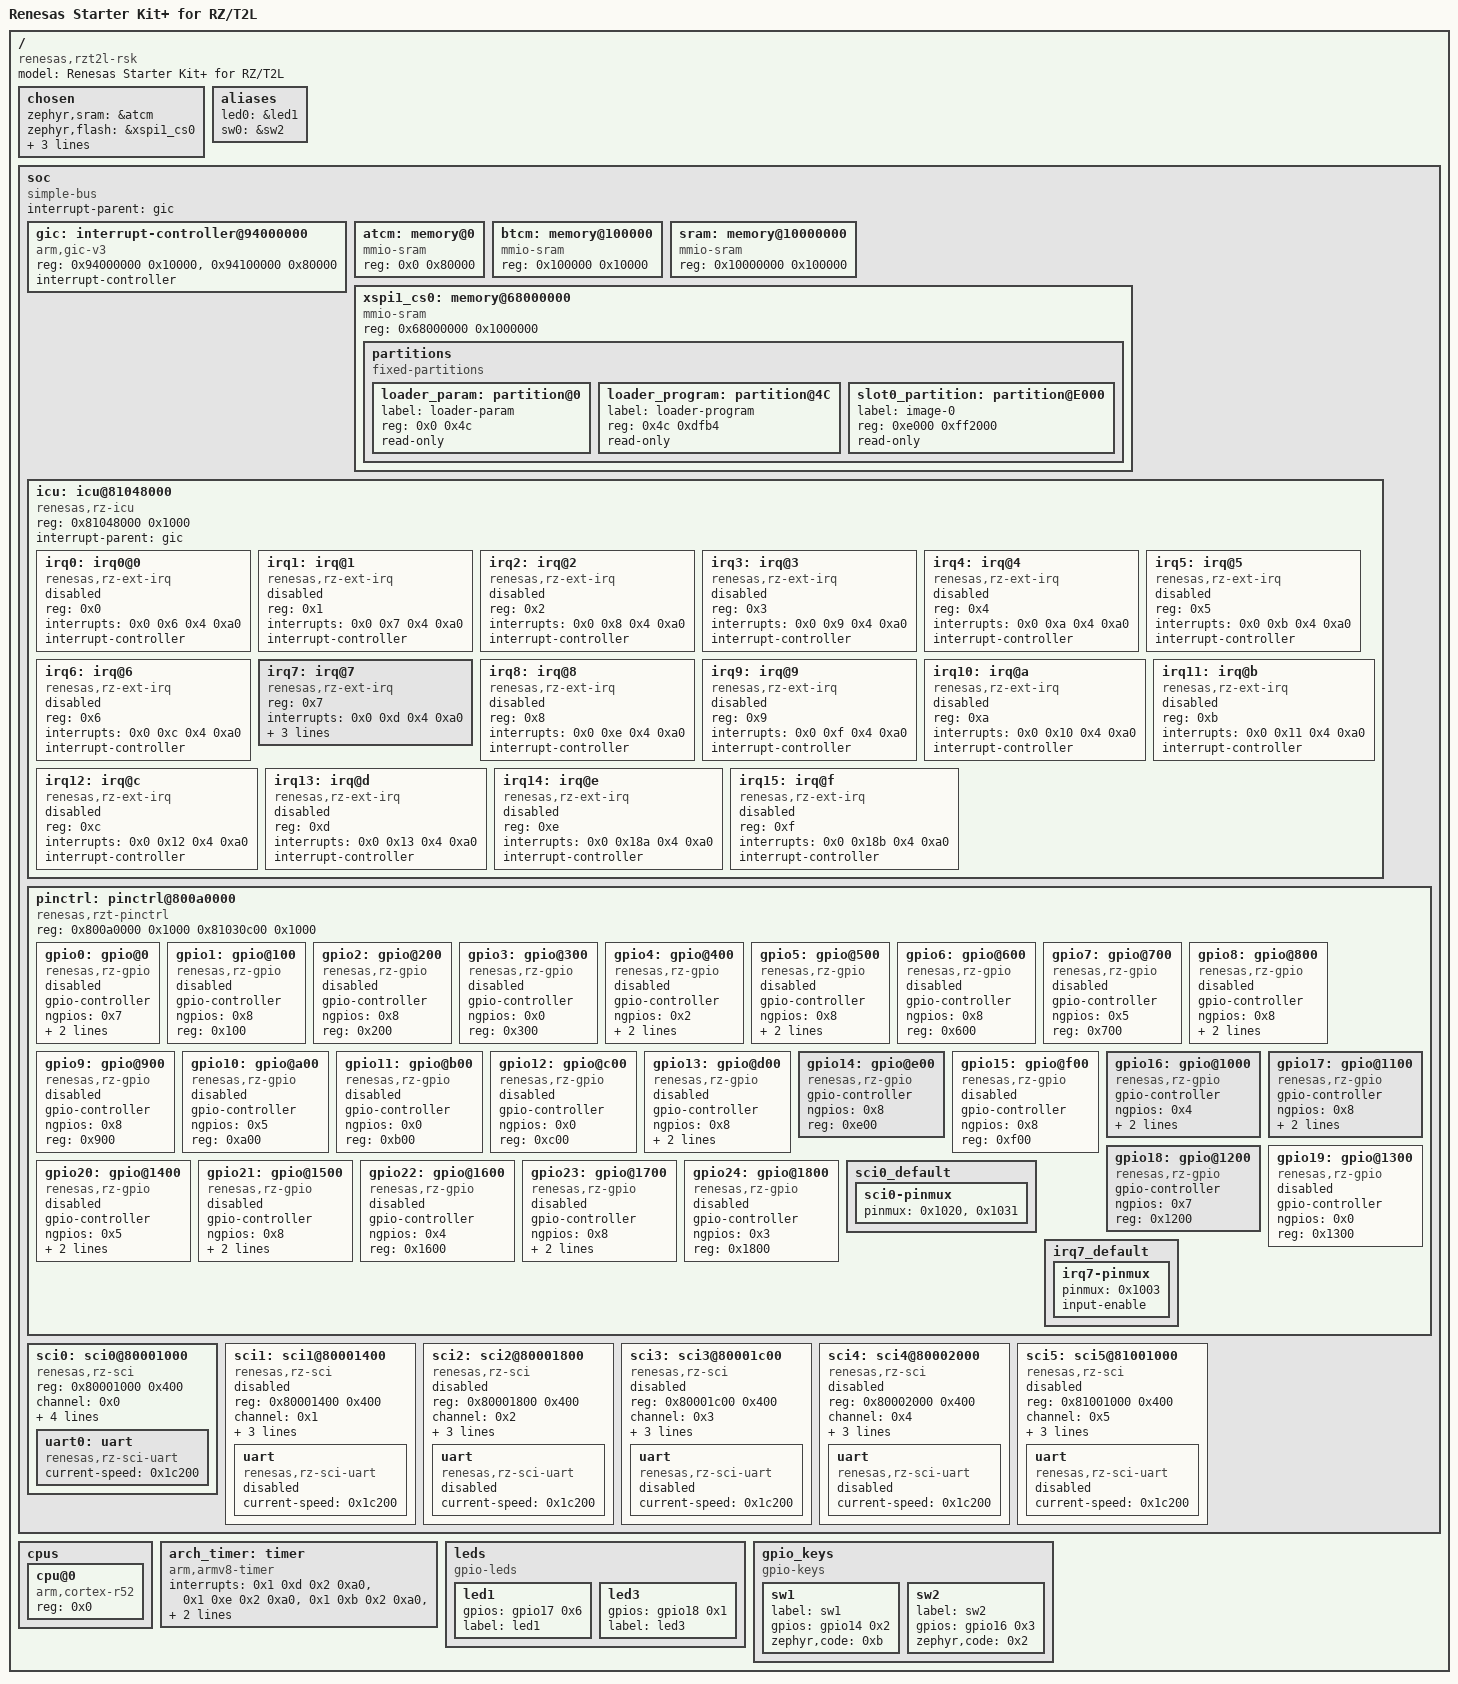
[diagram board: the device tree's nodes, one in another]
/dts-v1/;

/* node '/' defined in zephyr/dts/common/skeleton.dtsi:9 */
/ {
	#address-cells = < 0x1 >;                  /* in zephyr/dts/arm/renesas/rz/rzt/r9a07g074.dtsi:13 */
	#size-cells = < 0x1 >;                     /* in zephyr/dts/arm/renesas/rz/rzt/r9a07g074.dtsi:14 */
	model = "Renesas Starter Kit+ for RZ/T2L"; /* in zephyr/boards/renesas/rzt2l_rsk/rzt2l_rsk.dts:14 */
	compatible = "renesas,rzt2l-rsk";          /* in zephyr/boards/renesas/rzt2l_rsk/rzt2l_rsk.dts:15 */

	/* node '/chosen' defined in zephyr/dts/common/skeleton.dtsi:13 */
	chosen {
		zephyr,sram = &atcm;                      /* in zephyr/boards/renesas/rzt2l_rsk/rzt2l_rsk.dts:18 */
		zephyr,flash = &xspi1_cs0;                /* in zephyr/boards/renesas/rzt2l_rsk/rzt2l_rsk.dts:19 */
		zephyr,code-partition = &slot0_partition; /* in zephyr/boards/renesas/rzt2l_rsk/rzt2l_rsk.dts:20 */
		zephyr,console = &uart0;                  /* in zephyr/boards/renesas/rzt2l_rsk/rzt2l_rsk.dts:21 */
		zephyr,shell-uart = &uart0;               /* in zephyr/boards/renesas/rzt2l_rsk/rzt2l_rsk.dts:22 */
	};

	/* node '/aliases' defined in zephyr/dts/common/skeleton.dtsi:15 */
	aliases {
		led0 = &led1; /* in zephyr/boards/renesas/rzt2l_rsk/rzt2l_rsk.dts:26 */
		sw0 = &sw2;   /* in zephyr/boards/renesas/rzt2l_rsk/rzt2l_rsk.dts:27 */
	};

	/* node '/soc' defined in zephyr/dts/arm/armv8-r.dtsi:10 */
	soc {
		#address-cells = < 0x1 >;    /* in zephyr/dts/arm/armv8-r.dtsi:11 */
		#size-cells = < 0x1 >;       /* in zephyr/dts/arm/armv8-r.dtsi:12 */
		compatible = "simple-bus";   /* in zephyr/dts/arm/armv8-r.dtsi:13 */
		ranges;                      /* in zephyr/dts/arm/armv8-r.dtsi:14 */
		interrupt-parent = < &gic >; /* in zephyr/dts/arm/renesas/rz/rzt/r9a07g074.dtsi:37 */

		/* node '/soc/interrupt-controller@94000000' defined in zephyr/dts/arm/renesas/rz/rzt/r9a07g074.dtsi:39 */
		gic: interrupt-controller@94000000 {
			compatible = "arm,gic-v3",
			             "arm,gic";       /* in zephyr/dts/arm/renesas/rz/rzt/r9a07g074.dtsi:40 */
			reg = < 0x94000000 0x10000 >,
			      < 0x94100000 0x80000 >; /* in zephyr/dts/arm/renesas/rz/rzt/r9a07g074.dtsi:41 */
			interrupt-controller;         /* in zephyr/dts/arm/renesas/rz/rzt/r9a07g074.dtsi:43 */
			#interrupt-cells = < 0x4 >;   /* in zephyr/dts/arm/renesas/rz/rzt/r9a07g074.dtsi:44 */
			status = "okay";              /* in zephyr/dts/arm/renesas/rz/rzt/r9a07g074.dtsi:45 */
			phandle = < 0x1 >;            /* in zephyr/dts/arm/renesas/rz/rzt/r9a07g074.dtsi:37 */
		};

		/* node '/soc/memory@0' defined in zephyr/dts/arm/renesas/rz/rzt/r9a07g074.dtsi:48 */
		atcm: memory@0 {
			compatible = "mmio-sram"; /* in zephyr/dts/arm/renesas/rz/rzt/r9a07g074.dtsi:49 */
			reg = < 0x0 0x80000 >;    /* in zephyr/dts/arm/renesas/rz/rzt/r9a07g074.dtsi:50 */
		};

		/* node '/soc/memory@100000' defined in zephyr/dts/arm/renesas/rz/rzt/r9a07g074.dtsi:53 */
		btcm: memory@100000 {
			compatible = "mmio-sram";   /* in zephyr/dts/arm/renesas/rz/rzt/r9a07g074.dtsi:54 */
			reg = < 0x100000 0x10000 >; /* in zephyr/dts/arm/renesas/rz/rzt/r9a07g074.dtsi:55 */
		};

		/* node '/soc/memory@10000000' defined in zephyr/dts/arm/renesas/rz/rzt/r9a07g074.dtsi:58 */
		sram: memory@10000000 {
			compatible = "mmio-sram";      /* in zephyr/dts/arm/renesas/rz/rzt/r9a07g074.dtsi:59 */
			reg = < 0x10000000 0x100000 >; /* in zephyr/dts/arm/renesas/rz/rzt/r9a07g074.dtsi:60 */
		};

		/* node '/soc/memory@68000000' defined in zephyr/dts/arm/renesas/rz/rzt/r9a07g074.dtsi:63 */
		xspi1_cs0: memory@68000000 {
			compatible = "mmio-sram";       /* in zephyr/dts/arm/renesas/rz/rzt/r9a07g074.dtsi:64 */
			reg = < 0x68000000 0x1000000 >; /* in zephyr/dts/arm/renesas/rz/rzt/r9a07g074.dtsi:65 */

			/* node '/soc/memory@68000000/partitions' defined in zephyr/dts/arm/renesas/rz/rzt/r9a07g074.dtsi:67 */
			partitions {
				compatible = "fixed-partitions"; /* in zephyr/dts/arm/renesas/rz/rzt/r9a07g074.dtsi:68 */
				#address-cells = < 0x1 >;        /* in zephyr/dts/arm/renesas/rz/rzt/r9a07g074.dtsi:69 */
				#size-cells = < 0x1 >;           /* in zephyr/dts/arm/renesas/rz/rzt/r9a07g074.dtsi:70 */

				/* node '/soc/memory@68000000/partitions/partition@0' defined in zephyr/dts/arm/renesas/rz/rzt/r9a07g074.dtsi:72 */
				loader_param: partition@0 {
					label = "loader-param"; /* in zephyr/dts/arm/renesas/rz/rzt/r9a07g074.dtsi:73 */
					reg = < 0x0 0x4c >;     /* in zephyr/dts/arm/renesas/rz/rzt/r9a07g074.dtsi:74 */
					read-only;              /* in zephyr/dts/arm/renesas/rz/rzt/r9a07g074.dtsi:75 */
				};

				/* node '/soc/memory@68000000/partitions/partition@4C' defined in zephyr/dts/arm/renesas/rz/rzt/r9a07g074.dtsi:78 */
				loader_program: partition@4C {
					label = "loader-program"; /* in zephyr/dts/arm/renesas/rz/rzt/r9a07g074.dtsi:79 */
					reg = < 0x4c 0xdfb4 >;    /* in zephyr/dts/arm/renesas/rz/rzt/r9a07g074.dtsi:80 */
					read-only;                /* in zephyr/dts/arm/renesas/rz/rzt/r9a07g074.dtsi:81 */
				};

				/* node '/soc/memory@68000000/partitions/partition@E000' defined in zephyr/dts/arm/renesas/rz/rzt/r9a07g074.dtsi:84 */
				slot0_partition: partition@E000 {
					label = "image-0";         /* in zephyr/dts/arm/renesas/rz/rzt/r9a07g074.dtsi:85 */
					reg = < 0xe000 0xff2000 >; /* in zephyr/dts/arm/renesas/rz/rzt/r9a07g074.dtsi:86 */
					read-only;                 /* in zephyr/dts/arm/renesas/rz/rzt/r9a07g074.dtsi:87 */
				};
			};
		};

		/* node '/soc/icu@81048000' defined in zephyr/dts/arm/renesas/rz/rzt/r9a07g074.dtsi:92 */
		icu: icu@81048000 {
			compatible = "renesas,rz-icu"; /* in zephyr/dts/arm/renesas/rz/rzt/r9a07g074.dtsi:93 */
			reg = < 0x81048000 0x1000 >;   /* in zephyr/dts/arm/renesas/rz/rzt/r9a07g074.dtsi:94 */
			interrupt-parent = < &gic >;   /* in zephyr/dts/arm/renesas/rz/rzt/r9a07g074.dtsi:95 */
			#address-cells = < 0x1 >;      /* in zephyr/dts/arm/renesas/rz/rzt/r9a07g074.dtsi:96 */
			#size-cells = < 0x0 >;         /* in zephyr/dts/arm/renesas/rz/rzt/r9a07g074.dtsi:97 */

			/* node '/soc/icu@81048000/irq0@0' defined in zephyr/dts/arm/renesas/rz/rzt/r9a07g074.dtsi:99 */
			irq0: irq0@0 {
				compatible = "renesas,rz-ext-irq"; /* in zephyr/dts/arm/renesas/rz/rzt/r9a07g074.dtsi:100 */
				reg = < 0x0 >;                     /* in zephyr/dts/arm/renesas/rz/rzt/r9a07g074.dtsi:101 */
				interrupts = < 0x0 0x6 0x4 0xa0 >; /* in zephyr/dts/arm/renesas/rz/rzt/r9a07g074.dtsi:102 */
				interrupt-controller;              /* in zephyr/dts/arm/renesas/rz/rzt/r9a07g074.dtsi:103 */
				#interrupt-cells = < 0x2 >;        /* in zephyr/dts/arm/renesas/rz/rzt/r9a07g074.dtsi:104 */
				status = "disabled";               /* in zephyr/dts/arm/renesas/rz/rzt/r9a07g074.dtsi:105 */
			};

			/* node '/soc/icu@81048000/irq@1' defined in zephyr/dts/arm/renesas/rz/rzt/r9a07g074.dtsi:108 */
			irq1: irq@1 {
				compatible = "renesas,rz-ext-irq"; /* in zephyr/dts/arm/renesas/rz/rzt/r9a07g074.dtsi:109 */
				reg = < 0x1 >;                     /* in zephyr/dts/arm/renesas/rz/rzt/r9a07g074.dtsi:110 */
				interrupts = < 0x0 0x7 0x4 0xa0 >; /* in zephyr/dts/arm/renesas/rz/rzt/r9a07g074.dtsi:111 */
				interrupt-controller;              /* in zephyr/dts/arm/renesas/rz/rzt/r9a07g074.dtsi:112 */
				#interrupt-cells = < 0x2 >;        /* in zephyr/dts/arm/renesas/rz/rzt/r9a07g074.dtsi:113 */
				status = "disabled";               /* in zephyr/dts/arm/renesas/rz/rzt/r9a07g074.dtsi:114 */
			};

			/* node '/soc/icu@81048000/irq@2' defined in zephyr/dts/arm/renesas/rz/rzt/r9a07g074.dtsi:117 */
			irq2: irq@2 {
				compatible = "renesas,rz-ext-irq"; /* in zephyr/dts/arm/renesas/rz/rzt/r9a07g074.dtsi:118 */
				reg = < 0x2 >;                     /* in zephyr/dts/arm/renesas/rz/rzt/r9a07g074.dtsi:119 */
				interrupts = < 0x0 0x8 0x4 0xa0 >; /* in zephyr/dts/arm/renesas/rz/rzt/r9a07g074.dtsi:120 */
				interrupt-controller;              /* in zephyr/dts/arm/renesas/rz/rzt/r9a07g074.dtsi:121 */
				#interrupt-cells = < 0x2 >;        /* in zephyr/dts/arm/renesas/rz/rzt/r9a07g074.dtsi:122 */
				status = "disabled";               /* in zephyr/dts/arm/renesas/rz/rzt/r9a07g074.dtsi:123 */
			};

			/* node '/soc/icu@81048000/irq@3' defined in zephyr/dts/arm/renesas/rz/rzt/r9a07g074.dtsi:126 */
			irq3: irq@3 {
				compatible = "renesas,rz-ext-irq"; /* in zephyr/dts/arm/renesas/rz/rzt/r9a07g074.dtsi:127 */
				reg = < 0x3 >;                     /* in zephyr/dts/arm/renesas/rz/rzt/r9a07g074.dtsi:128 */
				interrupts = < 0x0 0x9 0x4 0xa0 >; /* in zephyr/dts/arm/renesas/rz/rzt/r9a07g074.dtsi:129 */
				interrupt-controller;              /* in zephyr/dts/arm/renesas/rz/rzt/r9a07g074.dtsi:130 */
				#interrupt-cells = < 0x2 >;        /* in zephyr/dts/arm/renesas/rz/rzt/r9a07g074.dtsi:131 */
				status = "disabled";               /* in zephyr/dts/arm/renesas/rz/rzt/r9a07g074.dtsi:132 */
			};

			/* node '/soc/icu@81048000/irq@4' defined in zephyr/dts/arm/renesas/rz/rzt/r9a07g074.dtsi:135 */
			irq4: irq@4 {
				compatible = "renesas,rz-ext-irq"; /* in zephyr/dts/arm/renesas/rz/rzt/r9a07g074.dtsi:136 */
				reg = < 0x4 >;                     /* in zephyr/dts/arm/renesas/rz/rzt/r9a07g074.dtsi:137 */
				interrupts = < 0x0 0xa 0x4 0xa0 >; /* in zephyr/dts/arm/renesas/rz/rzt/r9a07g074.dtsi:138 */
				interrupt-controller;              /* in zephyr/dts/arm/renesas/rz/rzt/r9a07g074.dtsi:139 */
				#interrupt-cells = < 0x2 >;        /* in zephyr/dts/arm/renesas/rz/rzt/r9a07g074.dtsi:140 */
				status = "disabled";               /* in zephyr/dts/arm/renesas/rz/rzt/r9a07g074.dtsi:141 */
			};

			/* node '/soc/icu@81048000/irq@5' defined in zephyr/dts/arm/renesas/rz/rzt/r9a07g074.dtsi:144 */
			irq5: irq@5 {
				compatible = "renesas,rz-ext-irq"; /* in zephyr/dts/arm/renesas/rz/rzt/r9a07g074.dtsi:145 */
				reg = < 0x5 >;                     /* in zephyr/dts/arm/renesas/rz/rzt/r9a07g074.dtsi:146 */
				interrupts = < 0x0 0xb 0x4 0xa0 >; /* in zephyr/dts/arm/renesas/rz/rzt/r9a07g074.dtsi:147 */
				interrupt-controller;              /* in zephyr/dts/arm/renesas/rz/rzt/r9a07g074.dtsi:148 */
				#interrupt-cells = < 0x2 >;        /* in zephyr/dts/arm/renesas/rz/rzt/r9a07g074.dtsi:149 */
				status = "disabled";               /* in zephyr/dts/arm/renesas/rz/rzt/r9a07g074.dtsi:150 */
			};

			/* node '/soc/icu@81048000/irq@6' defined in zephyr/dts/arm/renesas/rz/rzt/r9a07g074.dtsi:153 */
			irq6: irq@6 {
				compatible = "renesas,rz-ext-irq"; /* in zephyr/dts/arm/renesas/rz/rzt/r9a07g074.dtsi:154 */
				reg = < 0x6 >;                     /* in zephyr/dts/arm/renesas/rz/rzt/r9a07g074.dtsi:155 */
				interrupts = < 0x0 0xc 0x4 0xa0 >; /* in zephyr/dts/arm/renesas/rz/rzt/r9a07g074.dtsi:156 */
				interrupt-controller;              /* in zephyr/dts/arm/renesas/rz/rzt/r9a07g074.dtsi:157 */
				#interrupt-cells = < 0x2 >;        /* in zephyr/dts/arm/renesas/rz/rzt/r9a07g074.dtsi:158 */
				status = "disabled";               /* in zephyr/dts/arm/renesas/rz/rzt/r9a07g074.dtsi:159 */
			};

			/* node '/soc/icu@81048000/irq@7' defined in zephyr/dts/arm/renesas/rz/rzt/r9a07g074.dtsi:162 */
			irq7: irq@7 {
				compatible = "renesas,rz-ext-irq"; /* in zephyr/dts/arm/renesas/rz/rzt/r9a07g074.dtsi:163 */
				reg = < 0x7 >;                     /* in zephyr/dts/arm/renesas/rz/rzt/r9a07g074.dtsi:164 */
				interrupts = < 0x0 0xd 0x4 0xa0 >; /* in zephyr/dts/arm/renesas/rz/rzt/r9a07g074.dtsi:165 */
				interrupt-controller;              /* in zephyr/dts/arm/renesas/rz/rzt/r9a07g074.dtsi:166 */
				#interrupt-cells = < 0x2 >;        /* in zephyr/dts/arm/renesas/rz/rzt/r9a07g074.dtsi:167 */
				trigger-type = "falling";          /* in zephyr/boards/renesas/rzt2l_rsk/rzt2l_rsk.dts:90 */
				pinctrl-0 = < &irq7_default >;     /* in zephyr/boards/renesas/rzt2l_rsk/rzt2l_rsk.dts:91 */
				pinctrl-names = "default";         /* in zephyr/boards/renesas/rzt2l_rsk/rzt2l_rsk.dts:92 */
				status = "okay";                   /* in zephyr/boards/renesas/rzt2l_rsk/rzt2l_rsk.dts:93 */
			};

			/* node '/soc/icu@81048000/irq@8' defined in zephyr/dts/arm/renesas/rz/rzt/r9a07g074.dtsi:171 */
			irq8: irq@8 {
				compatible = "renesas,rz-ext-irq"; /* in zephyr/dts/arm/renesas/rz/rzt/r9a07g074.dtsi:172 */
				reg = < 0x8 >;                     /* in zephyr/dts/arm/renesas/rz/rzt/r9a07g074.dtsi:173 */
				interrupts = < 0x0 0xe 0x4 0xa0 >; /* in zephyr/dts/arm/renesas/rz/rzt/r9a07g074.dtsi:174 */
				interrupt-controller;              /* in zephyr/dts/arm/renesas/rz/rzt/r9a07g074.dtsi:175 */
				#interrupt-cells = < 0x2 >;        /* in zephyr/dts/arm/renesas/rz/rzt/r9a07g074.dtsi:176 */
				status = "disabled";               /* in zephyr/dts/arm/renesas/rz/rzt/r9a07g074.dtsi:177 */
			};

			/* node '/soc/icu@81048000/irq@9' defined in zephyr/dts/arm/renesas/rz/rzt/r9a07g074.dtsi:180 */
			irq9: irq@9 {
				compatible = "renesas,rz-ext-irq"; /* in zephyr/dts/arm/renesas/rz/rzt/r9a07g074.dtsi:181 */
				reg = < 0x9 >;                     /* in zephyr/dts/arm/renesas/rz/rzt/r9a07g074.dtsi:182 */
				interrupts = < 0x0 0xf 0x4 0xa0 >; /* in zephyr/dts/arm/renesas/rz/rzt/r9a07g074.dtsi:183 */
				interrupt-controller;              /* in zephyr/dts/arm/renesas/rz/rzt/r9a07g074.dtsi:184 */
				#interrupt-cells = < 0x2 >;        /* in zephyr/dts/arm/renesas/rz/rzt/r9a07g074.dtsi:185 */
				status = "disabled";               /* in zephyr/dts/arm/renesas/rz/rzt/r9a07g074.dtsi:186 */
			};

			/* node '/soc/icu@81048000/irq@a' defined in zephyr/dts/arm/renesas/rz/rzt/r9a07g074.dtsi:189 */
			irq10: irq@a {
				compatible = "renesas,rz-ext-irq";  /* in zephyr/dts/arm/renesas/rz/rzt/r9a07g074.dtsi:190 */
				reg = < 0xa >;                      /* in zephyr/dts/arm/renesas/rz/rzt/r9a07g074.dtsi:191 */
				interrupts = < 0x0 0x10 0x4 0xa0 >; /* in zephyr/dts/arm/renesas/rz/rzt/r9a07g074.dtsi:192 */
				interrupt-controller;               /* in zephyr/dts/arm/renesas/rz/rzt/r9a07g074.dtsi:193 */
				#interrupt-cells = < 0x2 >;         /* in zephyr/dts/arm/renesas/rz/rzt/r9a07g074.dtsi:194 */
				status = "disabled";                /* in zephyr/dts/arm/renesas/rz/rzt/r9a07g074.dtsi:195 */
			};

			/* node '/soc/icu@81048000/irq@b' defined in zephyr/dts/arm/renesas/rz/rzt/r9a07g074.dtsi:198 */
			irq11: irq@b {
				compatible = "renesas,rz-ext-irq";  /* in zephyr/dts/arm/renesas/rz/rzt/r9a07g074.dtsi:199 */
				reg = < 0xb >;                      /* in zephyr/dts/arm/renesas/rz/rzt/r9a07g074.dtsi:200 */
				interrupts = < 0x0 0x11 0x4 0xa0 >; /* in zephyr/dts/arm/renesas/rz/rzt/r9a07g074.dtsi:201 */
				interrupt-controller;               /* in zephyr/dts/arm/renesas/rz/rzt/r9a07g074.dtsi:202 */
				#interrupt-cells = < 0x2 >;         /* in zephyr/dts/arm/renesas/rz/rzt/r9a07g074.dtsi:203 */
				status = "disabled";                /* in zephyr/dts/arm/renesas/rz/rzt/r9a07g074.dtsi:204 */
			};

			/* node '/soc/icu@81048000/irq@c' defined in zephyr/dts/arm/renesas/rz/rzt/r9a07g074.dtsi:207 */
			irq12: irq@c {
				compatible = "renesas,rz-ext-irq";  /* in zephyr/dts/arm/renesas/rz/rzt/r9a07g074.dtsi:208 */
				reg = < 0xc >;                      /* in zephyr/dts/arm/renesas/rz/rzt/r9a07g074.dtsi:209 */
				interrupts = < 0x0 0x12 0x4 0xa0 >; /* in zephyr/dts/arm/renesas/rz/rzt/r9a07g074.dtsi:210 */
				interrupt-controller;               /* in zephyr/dts/arm/renesas/rz/rzt/r9a07g074.dtsi:211 */
				#interrupt-cells = < 0x2 >;         /* in zephyr/dts/arm/renesas/rz/rzt/r9a07g074.dtsi:212 */
				status = "disabled";                /* in zephyr/dts/arm/renesas/rz/rzt/r9a07g074.dtsi:213 */
			};

			/* node '/soc/icu@81048000/irq@d' defined in zephyr/dts/arm/renesas/rz/rzt/r9a07g074.dtsi:216 */
			irq13: irq@d {
				compatible = "renesas,rz-ext-irq";  /* in zephyr/dts/arm/renesas/rz/rzt/r9a07g074.dtsi:217 */
				reg = < 0xd >;                      /* in zephyr/dts/arm/renesas/rz/rzt/r9a07g074.dtsi:218 */
				interrupts = < 0x0 0x13 0x4 0xa0 >; /* in zephyr/dts/arm/renesas/rz/rzt/r9a07g074.dtsi:219 */
				interrupt-controller;               /* in zephyr/dts/arm/renesas/rz/rzt/r9a07g074.dtsi:220 */
				#interrupt-cells = < 0x2 >;         /* in zephyr/dts/arm/renesas/rz/rzt/r9a07g074.dtsi:221 */
				status = "disabled";                /* in zephyr/dts/arm/renesas/rz/rzt/r9a07g074.dtsi:222 */
			};

			/* node '/soc/icu@81048000/irq@e' defined in zephyr/dts/arm/renesas/rz/rzt/r9a07g074.dtsi:225 */
			irq14: irq@e {
				compatible = "renesas,rz-ext-irq";   /* in zephyr/dts/arm/renesas/rz/rzt/r9a07g074.dtsi:226 */
				reg = < 0xe >;                       /* in zephyr/dts/arm/renesas/rz/rzt/r9a07g074.dtsi:227 */
				interrupts = < 0x0 0x18a 0x4 0xa0 >; /* in zephyr/dts/arm/renesas/rz/rzt/r9a07g074.dtsi:228 */
				interrupt-controller;                /* in zephyr/dts/arm/renesas/rz/rzt/r9a07g074.dtsi:229 */
				#interrupt-cells = < 0x2 >;          /* in zephyr/dts/arm/renesas/rz/rzt/r9a07g074.dtsi:230 */
				status = "disabled";                 /* in zephyr/dts/arm/renesas/rz/rzt/r9a07g074.dtsi:231 */
			};

			/* node '/soc/icu@81048000/irq@f' defined in zephyr/dts/arm/renesas/rz/rzt/r9a07g074.dtsi:234 */
			irq15: irq@f {
				compatible = "renesas,rz-ext-irq";   /* in zephyr/dts/arm/renesas/rz/rzt/r9a07g074.dtsi:235 */
				reg = < 0xf >;                       /* in zephyr/dts/arm/renesas/rz/rzt/r9a07g074.dtsi:236 */
				interrupts = < 0x0 0x18b 0x4 0xa0 >; /* in zephyr/dts/arm/renesas/rz/rzt/r9a07g074.dtsi:237 */
				interrupt-controller;                /* in zephyr/dts/arm/renesas/rz/rzt/r9a07g074.dtsi:238 */
				#interrupt-cells = < 0x2 >;          /* in zephyr/dts/arm/renesas/rz/rzt/r9a07g074.dtsi:239 */
				status = "disabled";                 /* in zephyr/dts/arm/renesas/rz/rzt/r9a07g074.dtsi:240 */
			};
		};

		/* node '/soc/pinctrl@800a0000' defined in zephyr/dts/arm/renesas/rz/rzt/r9a07g074.dtsi:244 */
		pinctrl: pinctrl@800a0000 {
			compatible = "renesas,rzt-pinctrl";            /* in zephyr/dts/arm/renesas/rz/rzt/r9a07g074.dtsi:245 */
			reg = < 0x800a0000 0x1000 0x81030c00 0x1000 >; /* in zephyr/dts/arm/renesas/rz/rzt/r9a07g074.dtsi:246 */
			#address-cells = < 0x1 >;                      /* in zephyr/dts/arm/renesas/rz/rzt/r9a07g074.dtsi:247 */
			#size-cells = < 0x0 >;                         /* in zephyr/dts/arm/renesas/rz/rzt/r9a07g074.dtsi:248 */

			/* node '/soc/pinctrl@800a0000/gpio@0' defined in zephyr/dts/arm/renesas/rz/rzt/r9a07g074.dtsi:250 */
			gpio0: gpio@0 {
				compatible = "renesas,rz-gpio";     /* in zephyr/dts/arm/renesas/rz/rzt/r9a07g074.dtsi:251 */
				gpio-controller;                    /* in zephyr/dts/arm/renesas/rz/rzt/r9a07g074.dtsi:252 */
				#gpio-cells = < 0x2 >;              /* in zephyr/dts/arm/renesas/rz/rzt/r9a07g074.dtsi:253 */
				ngpios = < 0x7 >;                   /* in zephyr/dts/arm/renesas/rz/rzt/r9a07g074.dtsi:254 */
				gpio-reserved-ranges = < 0x4 0x2 >; /* in zephyr/dts/arm/renesas/rz/rzt/r9a07g074.dtsi:255 */
				reg = < 0x0 >;                      /* in zephyr/dts/arm/renesas/rz/rzt/r9a07g074.dtsi:256 */
				status = "disabled";                /* in zephyr/dts/arm/renesas/rz/rzt/r9a07g074.dtsi:257 */
			};

			/* node '/soc/pinctrl@800a0000/gpio@100' defined in zephyr/dts/arm/renesas/rz/rzt/r9a07g074.dtsi:260 */
			gpio1: gpio@100 {
				compatible = "renesas,rz-gpio"; /* in zephyr/dts/arm/renesas/rz/rzt/r9a07g074.dtsi:261 */
				gpio-controller;                /* in zephyr/dts/arm/renesas/rz/rzt/r9a07g074.dtsi:262 */
				#gpio-cells = < 0x2 >;          /* in zephyr/dts/arm/renesas/rz/rzt/r9a07g074.dtsi:263 */
				ngpios = < 0x8 >;               /* in zephyr/dts/arm/renesas/rz/rzt/r9a07g074.dtsi:264 */
				reg = < 0x100 >;                /* in zephyr/dts/arm/renesas/rz/rzt/r9a07g074.dtsi:265 */
				status = "disabled";            /* in zephyr/dts/arm/renesas/rz/rzt/r9a07g074.dtsi:266 */
			};

			/* node '/soc/pinctrl@800a0000/gpio@200' defined in zephyr/dts/arm/renesas/rz/rzt/r9a07g074.dtsi:269 */
			gpio2: gpio@200 {
				compatible = "renesas,rz-gpio"; /* in zephyr/dts/arm/renesas/rz/rzt/r9a07g074.dtsi:270 */
				gpio-controller;                /* in zephyr/dts/arm/renesas/rz/rzt/r9a07g074.dtsi:271 */
				#gpio-cells = < 0x2 >;          /* in zephyr/dts/arm/renesas/rz/rzt/r9a07g074.dtsi:272 */
				ngpios = < 0x8 >;               /* in zephyr/dts/arm/renesas/rz/rzt/r9a07g074.dtsi:273 */
				reg = < 0x200 >;                /* in zephyr/dts/arm/renesas/rz/rzt/r9a07g074.dtsi:274 */
				status = "disabled";            /* in zephyr/dts/arm/renesas/rz/rzt/r9a07g074.dtsi:275 */
			};

			/* node '/soc/pinctrl@800a0000/gpio@300' defined in zephyr/dts/arm/renesas/rz/rzt/r9a07g074.dtsi:278 */
			gpio3: gpio@300 {
				compatible = "renesas,rz-gpio"; /* in zephyr/dts/arm/renesas/rz/rzt/r9a07g074.dtsi:279 */
				gpio-controller;                /* in zephyr/dts/arm/renesas/rz/rzt/r9a07g074.dtsi:280 */
				#gpio-cells = < 0x2 >;          /* in zephyr/dts/arm/renesas/rz/rzt/r9a07g074.dtsi:281 */
				ngpios = < 0x0 >;               /* in zephyr/dts/arm/renesas/rz/rzt/r9a07g074.dtsi:282 */
				reg = < 0x300 >;                /* in zephyr/dts/arm/renesas/rz/rzt/r9a07g074.dtsi:283 */
				status = "disabled";            /* in zephyr/dts/arm/renesas/rz/rzt/r9a07g074.dtsi:284 */
			};

			/* node '/soc/pinctrl@800a0000/gpio@400' defined in zephyr/dts/arm/renesas/rz/rzt/r9a07g074.dtsi:287 */
			gpio4: gpio@400 {
				compatible = "renesas,rz-gpio";     /* in zephyr/dts/arm/renesas/rz/rzt/r9a07g074.dtsi:288 */
				gpio-controller;                    /* in zephyr/dts/arm/renesas/rz/rzt/r9a07g074.dtsi:289 */
				#gpio-cells = < 0x2 >;              /* in zephyr/dts/arm/renesas/rz/rzt/r9a07g074.dtsi:290 */
				ngpios = < 0x2 >;                   /* in zephyr/dts/arm/renesas/rz/rzt/r9a07g074.dtsi:291 */
				gpio-reserved-ranges = < 0x0 0x1 >; /* in zephyr/dts/arm/renesas/rz/rzt/r9a07g074.dtsi:292 */
				reg = < 0x400 >;                    /* in zephyr/dts/arm/renesas/rz/rzt/r9a07g074.dtsi:293 */
				status = "disabled";                /* in zephyr/dts/arm/renesas/rz/rzt/r9a07g074.dtsi:294 */
			};

			/* node '/soc/pinctrl@800a0000/gpio@500' defined in zephyr/dts/arm/renesas/rz/rzt/r9a07g074.dtsi:297 */
			gpio5: gpio@500 {
				compatible = "renesas,rz-gpio";     /* in zephyr/dts/arm/renesas/rz/rzt/r9a07g074.dtsi:298 */
				gpio-controller;                    /* in zephyr/dts/arm/renesas/rz/rzt/r9a07g074.dtsi:299 */
				#gpio-cells = < 0x2 >;              /* in zephyr/dts/arm/renesas/rz/rzt/r9a07g074.dtsi:300 */
				ngpios = < 0x8 >;                   /* in zephyr/dts/arm/renesas/rz/rzt/r9a07g074.dtsi:301 */
				gpio-reserved-ranges = < 0x0 0x5 >; /* in zephyr/dts/arm/renesas/rz/rzt/r9a07g074.dtsi:302 */
				reg = < 0x500 >;                    /* in zephyr/dts/arm/renesas/rz/rzt/r9a07g074.dtsi:303 */
				status = "disabled";                /* in zephyr/dts/arm/renesas/rz/rzt/r9a07g074.dtsi:304 */
			};

			/* node '/soc/pinctrl@800a0000/gpio@600' defined in zephyr/dts/arm/renesas/rz/rzt/r9a07g074.dtsi:307 */
			gpio6: gpio@600 {
				compatible = "renesas,rz-gpio"; /* in zephyr/dts/arm/renesas/rz/rzt/r9a07g074.dtsi:308 */
				gpio-controller;                /* in zephyr/dts/arm/renesas/rz/rzt/r9a07g074.dtsi:309 */
				#gpio-cells = < 0x2 >;          /* in zephyr/dts/arm/renesas/rz/rzt/r9a07g074.dtsi:310 */
				ngpios = < 0x8 >;               /* in zephyr/dts/arm/renesas/rz/rzt/r9a07g074.dtsi:311 */
				reg = < 0x600 >;                /* in zephyr/dts/arm/renesas/rz/rzt/r9a07g074.dtsi:312 */
				status = "disabled";            /* in zephyr/dts/arm/renesas/rz/rzt/r9a07g074.dtsi:313 */
			};

			/* node '/soc/pinctrl@800a0000/gpio@700' defined in zephyr/dts/arm/renesas/rz/rzt/r9a07g074.dtsi:316 */
			gpio7: gpio@700 {
				compatible = "renesas,rz-gpio"; /* in zephyr/dts/arm/renesas/rz/rzt/r9a07g074.dtsi:317 */
				gpio-controller;                /* in zephyr/dts/arm/renesas/rz/rzt/r9a07g074.dtsi:318 */
				#gpio-cells = < 0x2 >;          /* in zephyr/dts/arm/renesas/rz/rzt/r9a07g074.dtsi:319 */
				ngpios = < 0x5 >;               /* in zephyr/dts/arm/renesas/rz/rzt/r9a07g074.dtsi:320 */
				reg = < 0x700 >;                /* in zephyr/dts/arm/renesas/rz/rzt/r9a07g074.dtsi:321 */
				status = "disabled";            /* in zephyr/dts/arm/renesas/rz/rzt/r9a07g074.dtsi:322 */
			};

			/* node '/soc/pinctrl@800a0000/gpio@800' defined in zephyr/dts/arm/renesas/rz/rzt/r9a07g074.dtsi:325 */
			gpio8: gpio@800 {
				compatible = "renesas,rz-gpio";     /* in zephyr/dts/arm/renesas/rz/rzt/r9a07g074.dtsi:326 */
				gpio-controller;                    /* in zephyr/dts/arm/renesas/rz/rzt/r9a07g074.dtsi:327 */
				#gpio-cells = < 0x2 >;              /* in zephyr/dts/arm/renesas/rz/rzt/r9a07g074.dtsi:328 */
				ngpios = < 0x8 >;                   /* in zephyr/dts/arm/renesas/rz/rzt/r9a07g074.dtsi:329 */
				gpio-reserved-ranges = < 0x0 0x4 >; /* in zephyr/dts/arm/renesas/rz/rzt/r9a07g074.dtsi:330 */
				reg = < 0x800 >;                    /* in zephyr/dts/arm/renesas/rz/rzt/r9a07g074.dtsi:331 */
				status = "disabled";                /* in zephyr/dts/arm/renesas/rz/rzt/r9a07g074.dtsi:332 */
			};

			/* node '/soc/pinctrl@800a0000/gpio@900' defined in zephyr/dts/arm/renesas/rz/rzt/r9a07g074.dtsi:335 */
			gpio9: gpio@900 {
				compatible = "renesas,rz-gpio"; /* in zephyr/dts/arm/renesas/rz/rzt/r9a07g074.dtsi:336 */
				gpio-controller;                /* in zephyr/dts/arm/renesas/rz/rzt/r9a07g074.dtsi:337 */
				#gpio-cells = < 0x2 >;          /* in zephyr/dts/arm/renesas/rz/rzt/r9a07g074.dtsi:338 */
				ngpios = < 0x8 >;               /* in zephyr/dts/arm/renesas/rz/rzt/r9a07g074.dtsi:339 */
				reg = < 0x900 >;                /* in zephyr/dts/arm/renesas/rz/rzt/r9a07g074.dtsi:340 */
				status = "disabled";            /* in zephyr/dts/arm/renesas/rz/rzt/r9a07g074.dtsi:341 */
			};

			/* node '/soc/pinctrl@800a0000/gpio@a00' defined in zephyr/dts/arm/renesas/rz/rzt/r9a07g074.dtsi:344 */
			gpio10: gpio@a00 {
				compatible = "renesas,rz-gpio"; /* in zephyr/dts/arm/renesas/rz/rzt/r9a07g074.dtsi:345 */
				gpio-controller;                /* in zephyr/dts/arm/renesas/rz/rzt/r9a07g074.dtsi:346 */
				#gpio-cells = < 0x2 >;          /* in zephyr/dts/arm/renesas/rz/rzt/r9a07g074.dtsi:347 */
				ngpios = < 0x5 >;               /* in zephyr/dts/arm/renesas/rz/rzt/r9a07g074.dtsi:348 */
				reg = < 0xa00 >;                /* in zephyr/dts/arm/renesas/rz/rzt/r9a07g074.dtsi:349 */
				status = "disabled";            /* in zephyr/dts/arm/renesas/rz/rzt/r9a07g074.dtsi:350 */
			};

			/* node '/soc/pinctrl@800a0000/gpio@b00' defined in zephyr/dts/arm/renesas/rz/rzt/r9a07g074.dtsi:353 */
			gpio11: gpio@b00 {
				compatible = "renesas,rz-gpio"; /* in zephyr/dts/arm/renesas/rz/rzt/r9a07g074.dtsi:354 */
				gpio-controller;                /* in zephyr/dts/arm/renesas/rz/rzt/r9a07g074.dtsi:355 */
				#gpio-cells = < 0x2 >;          /* in zephyr/dts/arm/renesas/rz/rzt/r9a07g074.dtsi:356 */
				ngpios = < 0x0 >;               /* in zephyr/dts/arm/renesas/rz/rzt/r9a07g074.dtsi:357 */
				reg = < 0xb00 >;                /* in zephyr/dts/arm/renesas/rz/rzt/r9a07g074.dtsi:358 */
				status = "disabled";            /* in zephyr/dts/arm/renesas/rz/rzt/r9a07g074.dtsi:359 */
			};

			/* node '/soc/pinctrl@800a0000/gpio@c00' defined in zephyr/dts/arm/renesas/rz/rzt/r9a07g074.dtsi:362 */
			gpio12: gpio@c00 {
				compatible = "renesas,rz-gpio"; /* in zephyr/dts/arm/renesas/rz/rzt/r9a07g074.dtsi:363 */
				gpio-controller;                /* in zephyr/dts/arm/renesas/rz/rzt/r9a07g074.dtsi:364 */
				#gpio-cells = < 0x2 >;          /* in zephyr/dts/arm/renesas/rz/rzt/r9a07g074.dtsi:365 */
				ngpios = < 0x0 >;               /* in zephyr/dts/arm/renesas/rz/rzt/r9a07g074.dtsi:366 */
				reg = < 0xc00 >;                /* in zephyr/dts/arm/renesas/rz/rzt/r9a07g074.dtsi:367 */
				status = "disabled";            /* in zephyr/dts/arm/renesas/rz/rzt/r9a07g074.dtsi:368 */
			};

			/* node '/soc/pinctrl@800a0000/gpio@d00' defined in zephyr/dts/arm/renesas/rz/rzt/r9a07g074.dtsi:371 */
			gpio13: gpio@d00 {
				compatible = "renesas,rz-gpio";     /* in zephyr/dts/arm/renesas/rz/rzt/r9a07g074.dtsi:372 */
				gpio-controller;                    /* in zephyr/dts/arm/renesas/rz/rzt/r9a07g074.dtsi:373 */
				#gpio-cells = < 0x2 >;              /* in zephyr/dts/arm/renesas/rz/rzt/r9a07g074.dtsi:374 */
				ngpios = < 0x8 >;                   /* in zephyr/dts/arm/renesas/rz/rzt/r9a07g074.dtsi:375 */
				gpio-reserved-ranges = < 0x0 0x2 >; /* in zephyr/dts/arm/renesas/rz/rzt/r9a07g074.dtsi:376 */
				reg = < 0xd00 >;                    /* in zephyr/dts/arm/renesas/rz/rzt/r9a07g074.dtsi:377 */
				status = "disabled";                /* in zephyr/dts/arm/renesas/rz/rzt/r9a07g074.dtsi:378 */
			};

			/* node '/soc/pinctrl@800a0000/gpio@e00' defined in zephyr/dts/arm/renesas/rz/rzt/r9a07g074.dtsi:381 */
			gpio14: gpio@e00 {
				compatible = "renesas,rz-gpio"; /* in zephyr/dts/arm/renesas/rz/rzt/r9a07g074.dtsi:382 */
				gpio-controller;                /* in zephyr/dts/arm/renesas/rz/rzt/r9a07g074.dtsi:383 */
				#gpio-cells = < 0x2 >;          /* in zephyr/dts/arm/renesas/rz/rzt/r9a07g074.dtsi:384 */
				ngpios = < 0x8 >;               /* in zephyr/dts/arm/renesas/rz/rzt/r9a07g074.dtsi:385 */
				reg = < 0xe00 >;                /* in zephyr/dts/arm/renesas/rz/rzt/r9a07g074.dtsi:386 */
				status = "okay";                /* in zephyr/boards/renesas/rzt2l_rsk/rzt2l_rsk.dts:73 */
				phandle = < 0x6 >;              /* in zephyr/boards/renesas/rzt2l_rsk/rzt2l_rsk.dts:49 */
			};

			/* node '/soc/pinctrl@800a0000/gpio@f00' defined in zephyr/dts/arm/renesas/rz/rzt/r9a07g074.dtsi:390 */
			gpio15: gpio@f00 {
				compatible = "renesas,rz-gpio"; /* in zephyr/dts/arm/renesas/rz/rzt/r9a07g074.dtsi:391 */
				gpio-controller;                /* in zephyr/dts/arm/renesas/rz/rzt/r9a07g074.dtsi:392 */
				#gpio-cells = < 0x2 >;          /* in zephyr/dts/arm/renesas/rz/rzt/r9a07g074.dtsi:393 */
				ngpios = < 0x8 >;               /* in zephyr/dts/arm/renesas/rz/rzt/r9a07g074.dtsi:394 */
				reg = < 0xf00 >;                /* in zephyr/dts/arm/renesas/rz/rzt/r9a07g074.dtsi:395 */
				status = "disabled";            /* in zephyr/dts/arm/renesas/rz/rzt/r9a07g074.dtsi:396 */
			};

			/* node '/soc/pinctrl@800a0000/gpio@1000' defined in zephyr/dts/arm/renesas/rz/rzt/r9a07g074.dtsi:399 */
			gpio16: gpio@1000 {
				compatible = "renesas,rz-gpio"; /* in zephyr/dts/arm/renesas/rz/rzt/r9a07g074.dtsi:400 */
				gpio-controller;                /* in zephyr/dts/arm/renesas/rz/rzt/r9a07g074.dtsi:401 */
				#gpio-cells = < 0x2 >;          /* in zephyr/dts/arm/renesas/rz/rzt/r9a07g074.dtsi:402 */
				ngpios = < 0x4 >;               /* in zephyr/dts/arm/renesas/rz/rzt/r9a07g074.dtsi:403 */
				reg = < 0x1000 >;               /* in zephyr/dts/arm/renesas/rz/rzt/r9a07g074.dtsi:404 */
				irqs = < 0x3 0x7 >;             /* in zephyr/boards/renesas/rzt2l_rsk/rzt2l_rsk.dts:77 */
				status = "okay";                /* in zephyr/boards/renesas/rzt2l_rsk/rzt2l_rsk.dts:78 */
				phandle = < 0x7 >;              /* in zephyr/boards/renesas/rzt2l_rsk/rzt2l_rsk.dts:55 */
			};

			/* node '/soc/pinctrl@800a0000/gpio@1100' defined in zephyr/dts/arm/renesas/rz/rzt/r9a07g074.dtsi:408 */
			gpio17: gpio@1100 {
				compatible = "renesas,rz-gpio";     /* in zephyr/dts/arm/renesas/rz/rzt/r9a07g074.dtsi:409 */
				gpio-controller;                    /* in zephyr/dts/arm/renesas/rz/rzt/r9a07g074.dtsi:410 */
				#gpio-cells = < 0x2 >;              /* in zephyr/dts/arm/renesas/rz/rzt/r9a07g074.dtsi:411 */
				ngpios = < 0x8 >;                   /* in zephyr/dts/arm/renesas/rz/rzt/r9a07g074.dtsi:412 */
				gpio-reserved-ranges = < 0x1 0x2 >; /* in zephyr/dts/arm/renesas/rz/rzt/r9a07g074.dtsi:413 */
				reg = < 0x1100 >;                   /* in zephyr/dts/arm/renesas/rz/rzt/r9a07g074.dtsi:414 */
				status = "okay";                    /* in zephyr/boards/renesas/rzt2l_rsk/rzt2l_rsk.dts:82 */
				phandle = < 0x4 >;                  /* in zephyr/boards/renesas/rzt2l_rsk/rzt2l_rsk.dts:34 */
			};

			/* node '/soc/pinctrl@800a0000/gpio@1200' defined in zephyr/dts/arm/renesas/rz/rzt/r9a07g074.dtsi:418 */
			gpio18: gpio@1200 {
				compatible = "renesas,rz-gpio"; /* in zephyr/dts/arm/renesas/rz/rzt/r9a07g074.dtsi:419 */
				gpio-controller;                /* in zephyr/dts/arm/renesas/rz/rzt/r9a07g074.dtsi:420 */
				#gpio-cells = < 0x2 >;          /* in zephyr/dts/arm/renesas/rz/rzt/r9a07g074.dtsi:421 */
				ngpios = < 0x7 >;               /* in zephyr/dts/arm/renesas/rz/rzt/r9a07g074.dtsi:422 */
				reg = < 0x1200 >;               /* in zephyr/dts/arm/renesas/rz/rzt/r9a07g074.dtsi:423 */
				status = "okay";                /* in zephyr/boards/renesas/rzt2l_rsk/rzt2l_rsk.dts:86 */
				phandle = < 0x5 >;              /* in zephyr/boards/renesas/rzt2l_rsk/rzt2l_rsk.dts:39 */
			};

			/* node '/soc/pinctrl@800a0000/gpio@1300' defined in zephyr/dts/arm/renesas/rz/rzt/r9a07g074.dtsi:427 */
			gpio19: gpio@1300 {
				compatible = "renesas,rz-gpio"; /* in zephyr/dts/arm/renesas/rz/rzt/r9a07g074.dtsi:428 */
				gpio-controller;                /* in zephyr/dts/arm/renesas/rz/rzt/r9a07g074.dtsi:429 */
				#gpio-cells = < 0x2 >;          /* in zephyr/dts/arm/renesas/rz/rzt/r9a07g074.dtsi:430 */
				ngpios = < 0x0 >;               /* in zephyr/dts/arm/renesas/rz/rzt/r9a07g074.dtsi:431 */
				reg = < 0x1300 >;               /* in zephyr/dts/arm/renesas/rz/rzt/r9a07g074.dtsi:432 */
				status = "disabled";            /* in zephyr/dts/arm/renesas/rz/rzt/r9a07g074.dtsi:433 */
			};

			/* node '/soc/pinctrl@800a0000/gpio@1400' defined in zephyr/dts/arm/renesas/rz/rzt/r9a07g074.dtsi:436 */
			gpio20: gpio@1400 {
				compatible = "renesas,rz-gpio";     /* in zephyr/dts/arm/renesas/rz/rzt/r9a07g074.dtsi:437 */
				gpio-controller;                    /* in zephyr/dts/arm/renesas/rz/rzt/r9a07g074.dtsi:438 */
				#gpio-cells = < 0x2 >;              /* in zephyr/dts/arm/renesas/rz/rzt/r9a07g074.dtsi:439 */
				ngpios = < 0x5 >;                   /* in zephyr/dts/arm/renesas/rz/rzt/r9a07g074.dtsi:440 */
				gpio-reserved-ranges = < 0x0 0x3 >; /* in zephyr/dts/arm/renesas/rz/rzt/r9a07g074.dtsi:441 */
				reg = < 0x1400 >;                   /* in zephyr/dts/arm/renesas/rz/rzt/r9a07g074.dtsi:442 */
				status = "disabled";                /* in zephyr/dts/arm/renesas/rz/rzt/r9a07g074.dtsi:443 */
			};

			/* node '/soc/pinctrl@800a0000/gpio@1500' defined in zephyr/dts/arm/renesas/rz/rzt/r9a07g074.dtsi:446 */
			gpio21: gpio@1500 {
				compatible = "renesas,rz-gpio";     /* in zephyr/dts/arm/renesas/rz/rzt/r9a07g074.dtsi:447 */
				gpio-controller;                    /* in zephyr/dts/arm/renesas/rz/rzt/r9a07g074.dtsi:448 */
				#gpio-cells = < 0x2 >;              /* in zephyr/dts/arm/renesas/rz/rzt/r9a07g074.dtsi:449 */
				ngpios = < 0x8 >;                   /* in zephyr/dts/arm/renesas/rz/rzt/r9a07g074.dtsi:450 */
				gpio-reserved-ranges = < 0x0 0x1 >; /* in zephyr/dts/arm/renesas/rz/rzt/r9a07g074.dtsi:451 */
				reg = < 0x1500 >;                   /* in zephyr/dts/arm/renesas/rz/rzt/r9a07g074.dtsi:452 */
				status = "disabled";                /* in zephyr/dts/arm/renesas/rz/rzt/r9a07g074.dtsi:453 */
			};

			/* node '/soc/pinctrl@800a0000/gpio@1600' defined in zephyr/dts/arm/renesas/rz/rzt/r9a07g074.dtsi:456 */
			gpio22: gpio@1600 {
				compatible = "renesas,rz-gpio"; /* in zephyr/dts/arm/renesas/rz/rzt/r9a07g074.dtsi:457 */
				gpio-controller;                /* in zephyr/dts/arm/renesas/rz/rzt/r9a07g074.dtsi:458 */
				#gpio-cells = < 0x2 >;          /* in zephyr/dts/arm/renesas/rz/rzt/r9a07g074.dtsi:459 */
				ngpios = < 0x4 >;               /* in zephyr/dts/arm/renesas/rz/rzt/r9a07g074.dtsi:460 */
				reg = < 0x1600 >;               /* in zephyr/dts/arm/renesas/rz/rzt/r9a07g074.dtsi:461 */
				status = "disabled";            /* in zephyr/dts/arm/renesas/rz/rzt/r9a07g074.dtsi:462 */
			};

			/* node '/soc/pinctrl@800a0000/gpio@1700' defined in zephyr/dts/arm/renesas/rz/rzt/r9a07g074.dtsi:465 */
			gpio23: gpio@1700 {
				compatible = "renesas,rz-gpio";     /* in zephyr/dts/arm/renesas/rz/rzt/r9a07g074.dtsi:466 */
				gpio-controller;                    /* in zephyr/dts/arm/renesas/rz/rzt/r9a07g074.dtsi:467 */
				#gpio-cells = < 0x2 >;              /* in zephyr/dts/arm/renesas/rz/rzt/r9a07g074.dtsi:468 */
				ngpios = < 0x8 >;                   /* in zephyr/dts/arm/renesas/rz/rzt/r9a07g074.dtsi:469 */
				gpio-reserved-ranges = < 0x0 0x7 >; /* in zephyr/dts/arm/renesas/rz/rzt/r9a07g074.dtsi:470 */
				reg = < 0x1700 >;                   /* in zephyr/dts/arm/renesas/rz/rzt/r9a07g074.dtsi:471 */
				status = "disabled";                /* in zephyr/dts/arm/renesas/rz/rzt/r9a07g074.dtsi:472 */
			};

			/* node '/soc/pinctrl@800a0000/gpio@1800' defined in zephyr/dts/arm/renesas/rz/rzt/r9a07g074.dtsi:475 */
			gpio24: gpio@1800 {
				compatible = "renesas,rz-gpio"; /* in zephyr/dts/arm/renesas/rz/rzt/r9a07g074.dtsi:476 */
				gpio-controller;                /* in zephyr/dts/arm/renesas/rz/rzt/r9a07g074.dtsi:477 */
				#gpio-cells = < 0x2 >;          /* in zephyr/dts/arm/renesas/rz/rzt/r9a07g074.dtsi:478 */
				ngpios = < 0x3 >;               /* in zephyr/dts/arm/renesas/rz/rzt/r9a07g074.dtsi:479 */
				reg = < 0x1800 >;               /* in zephyr/dts/arm/renesas/rz/rzt/r9a07g074.dtsi:480 */
				status = "disabled";            /* in zephyr/dts/arm/renesas/rz/rzt/r9a07g074.dtsi:481 */
			};

			/* node '/soc/pinctrl@800a0000/sci0_default' defined in zephyr/boards/renesas/rzt2l_rsk/rzt2l_rsk-pinctrl.dtsi:10 */
			sci0_default: sci0_default {
				phandle = < 0x3 >; /* in zephyr/boards/renesas/rzt2l_rsk/rzt2l_rsk.dts:62 */

				/* node '/soc/pinctrl@800a0000/sci0_default/sci0-pinmux' defined in zephyr/boards/renesas/rzt2l_rsk/rzt2l_rsk-pinctrl.dtsi:11 */
				sci0-pinmux {
					pinmux = < 0x1020 >,
					         < 0x1031 >; /* in zephyr/boards/renesas/rzt2l_rsk/rzt2l_rsk-pinctrl.dtsi:12 */
				};
			};

			/* node '/soc/pinctrl@800a0000/irq7_default' defined in zephyr/boards/renesas/rzt2l_rsk/rzt2l_rsk-pinctrl.dtsi:17 */
			irq7_default: irq7_default {
				phandle = < 0x2 >; /* in zephyr/boards/renesas/rzt2l_rsk/rzt2l_rsk.dts:91 */

				/* node '/soc/pinctrl@800a0000/irq7_default/irq7-pinmux' defined in zephyr/boards/renesas/rzt2l_rsk/rzt2l_rsk-pinctrl.dtsi:18 */
				irq7-pinmux {
					pinmux = < 0x1003 >; /* in zephyr/boards/renesas/rzt2l_rsk/rzt2l_rsk-pinctrl.dtsi:19 */
					input-enable;        /* in zephyr/boards/renesas/rzt2l_rsk/rzt2l_rsk-pinctrl.dtsi:20 */
				};
			};
		};

		/* node '/soc/sci0@80001000' defined in zephyr/dts/arm/renesas/rz/rzt/r9a07g074.dtsi:485 */
		sci0: sci0@80001000 {
			compatible = "renesas,rz-sci";       /* in zephyr/dts/arm/renesas/rz/rzt/r9a07g074.dtsi:486 */
			reg = < 0x80001000 0x400 >;          /* in zephyr/dts/arm/renesas/rz/rzt/r9a07g074.dtsi:487 */
			channel = < 0x0 >;                   /* in zephyr/dts/arm/renesas/rz/rzt/r9a07g074.dtsi:488 */
			interrupts = < 0x0 0x120 0x2 0xa0 >,
			             < 0x0 0x121 0x4 0xa0 >,
			             < 0x0 0x122 0x4 0xa0 >,
			             < 0x0 0x123 0x2 0xa0 >; /* in zephyr/dts/arm/renesas/rz/rzt/r9a07g074.dtsi:489 */
			interrupt-names = "eri",
			                  "rxi",
			                  "txi",
			                  "tei";             /* in zephyr/dts/arm/renesas/rz/rzt/r9a07g074.dtsi:493 */
			pinctrl-0 = < &sci0_default >;       /* in zephyr/boards/renesas/rzt2l_rsk/rzt2l_rsk.dts:62 */
			pinctrl-names = "default";           /* in zephyr/boards/renesas/rzt2l_rsk/rzt2l_rsk.dts:63 */
			status = "okay";                     /* in zephyr/boards/renesas/rzt2l_rsk/rzt2l_rsk.dts:64 */

			/* node '/soc/sci0@80001000/uart' defined in zephyr/dts/arm/renesas/rz/rzt/r9a07g074.dtsi:496 */
			uart0: uart {
				compatible = "renesas,rz-sci-uart"; /* in zephyr/dts/arm/renesas/rz/rzt/r9a07g074.dtsi:497 */
				current-speed = < 0x1c200 >;        /* in zephyr/boards/renesas/rzt2l_rsk/rzt2l_rsk.dts:67 */
				status = "okay";                    /* in zephyr/boards/renesas/rzt2l_rsk/rzt2l_rsk.dts:68 */
			};
		};

		/* node '/soc/sci1@80001400' defined in zephyr/dts/arm/renesas/rz/rzt/r9a07g074.dtsi:503 */
		sci1: sci1@80001400 {
			compatible = "renesas,rz-sci";       /* in zephyr/dts/arm/renesas/rz/rzt/r9a07g074.dtsi:504 */
			reg = < 0x80001400 0x400 >;          /* in zephyr/dts/arm/renesas/rz/rzt/r9a07g074.dtsi:505 */
			channel = < 0x1 >;                   /* in zephyr/dts/arm/renesas/rz/rzt/r9a07g074.dtsi:506 */
			interrupts = < 0x0 0x124 0x2 0xa0 >,
			             < 0x0 0x125 0x4 0xa0 >,
			             < 0x0 0x126 0x4 0xa0 >,
			             < 0x0 0x127 0x2 0xa0 >; /* in zephyr/dts/arm/renesas/rz/rzt/r9a07g074.dtsi:507 */
			interrupt-names = "eri",
			                  "rxi",
			                  "txi",
			                  "tei";             /* in zephyr/dts/arm/renesas/rz/rzt/r9a07g074.dtsi:511 */
			status = "disabled";                 /* in zephyr/dts/arm/renesas/rz/rzt/r9a07g074.dtsi:512 */

			/* node '/soc/sci1@80001400/uart' defined in zephyr/dts/arm/renesas/rz/rzt/r9a07g074.dtsi:514 */
			uart {
				compatible = "renesas,rz-sci-uart"; /* in zephyr/dts/arm/renesas/rz/rzt/r9a07g074.dtsi:515 */
				current-speed = < 0x1c200 >;        /* in zephyr/dts/arm/renesas/rz/rzt/r9a07g074.dtsi:516 */
				status = "disabled";                /* in zephyr/dts/arm/renesas/rz/rzt/r9a07g074.dtsi:517 */
			};
		};

		/* node '/soc/sci2@80001800' defined in zephyr/dts/arm/renesas/rz/rzt/r9a07g074.dtsi:521 */
		sci2: sci2@80001800 {
			compatible = "renesas,rz-sci";       /* in zephyr/dts/arm/renesas/rz/rzt/r9a07g074.dtsi:522 */
			reg = < 0x80001800 0x400 >;          /* in zephyr/dts/arm/renesas/rz/rzt/r9a07g074.dtsi:523 */
			channel = < 0x2 >;                   /* in zephyr/dts/arm/renesas/rz/rzt/r9a07g074.dtsi:524 */
			interrupts = < 0x0 0x128 0x2 0xa0 >,
			             < 0x0 0x129 0x4 0xa0 >,
			             < 0x0 0x12a 0x4 0xa0 >,
			             < 0x0 0x12b 0x2 0xa0 >; /* in zephyr/dts/arm/renesas/rz/rzt/r9a07g074.dtsi:525 */
			interrupt-names = "eri",
			                  "rxi",
			                  "txi",
			                  "tei";             /* in zephyr/dts/arm/renesas/rz/rzt/r9a07g074.dtsi:529 */
			status = "disabled";                 /* in zephyr/dts/arm/renesas/rz/rzt/r9a07g074.dtsi:530 */

			/* node '/soc/sci2@80001800/uart' defined in zephyr/dts/arm/renesas/rz/rzt/r9a07g074.dtsi:532 */
			uart {
				compatible = "renesas,rz-sci-uart"; /* in zephyr/dts/arm/renesas/rz/rzt/r9a07g074.dtsi:533 */
				current-speed = < 0x1c200 >;        /* in zephyr/dts/arm/renesas/rz/rzt/r9a07g074.dtsi:534 */
				status = "disabled";                /* in zephyr/dts/arm/renesas/rz/rzt/r9a07g074.dtsi:535 */
			};
		};

		/* node '/soc/sci3@80001c00' defined in zephyr/dts/arm/renesas/rz/rzt/r9a07g074.dtsi:539 */
		sci3: sci3@80001c00 {
			compatible = "renesas,rz-sci";       /* in zephyr/dts/arm/renesas/rz/rzt/r9a07g074.dtsi:540 */
			reg = < 0x80001c00 0x400 >;          /* in zephyr/dts/arm/renesas/rz/rzt/r9a07g074.dtsi:541 */
			channel = < 0x3 >;                   /* in zephyr/dts/arm/renesas/rz/rzt/r9a07g074.dtsi:542 */
			interrupts = < 0x0 0x12c 0x2 0xa0 >,
			             < 0x0 0x12d 0x4 0xa0 >,
			             < 0x0 0x12e 0x4 0xa0 >,
			             < 0x0 0x12f 0x2 0xa0 >; /* in zephyr/dts/arm/renesas/rz/rzt/r9a07g074.dtsi:543 */
			interrupt-names = "eri",
			                  "rxi",
			                  "txi",
			                  "tei";             /* in zephyr/dts/arm/renesas/rz/rzt/r9a07g074.dtsi:547 */
			status = "disabled";                 /* in zephyr/dts/arm/renesas/rz/rzt/r9a07g074.dtsi:548 */

			/* node '/soc/sci3@80001c00/uart' defined in zephyr/dts/arm/renesas/rz/rzt/r9a07g074.dtsi:550 */
			uart {
				compatible = "renesas,rz-sci-uart"; /* in zephyr/dts/arm/renesas/rz/rzt/r9a07g074.dtsi:551 */
				current-speed = < 0x1c200 >;        /* in zephyr/dts/arm/renesas/rz/rzt/r9a07g074.dtsi:552 */
				status = "disabled";                /* in zephyr/dts/arm/renesas/rz/rzt/r9a07g074.dtsi:553 */
			};
		};

		/* node '/soc/sci4@80002000' defined in zephyr/dts/arm/renesas/rz/rzt/r9a07g074.dtsi:557 */
		sci4: sci4@80002000 {
			compatible = "renesas,rz-sci";       /* in zephyr/dts/arm/renesas/rz/rzt/r9a07g074.dtsi:558 */
			reg = < 0x80002000 0x400 >;          /* in zephyr/dts/arm/renesas/rz/rzt/r9a07g074.dtsi:559 */
			channel = < 0x4 >;                   /* in zephyr/dts/arm/renesas/rz/rzt/r9a07g074.dtsi:560 */
			interrupts = < 0x0 0x130 0x2 0xa0 >,
			             < 0x0 0x131 0x4 0xa0 >,
			             < 0x0 0x132 0x4 0xa0 >,
			             < 0x0 0x133 0x2 0xa0 >; /* in zephyr/dts/arm/renesas/rz/rzt/r9a07g074.dtsi:561 */
			interrupt-names = "eri",
			                  "rxi",
			                  "txi",
			                  "tei";             /* in zephyr/dts/arm/renesas/rz/rzt/r9a07g074.dtsi:565 */
			status = "disabled";                 /* in zephyr/dts/arm/renesas/rz/rzt/r9a07g074.dtsi:566 */

			/* node '/soc/sci4@80002000/uart' defined in zephyr/dts/arm/renesas/rz/rzt/r9a07g074.dtsi:568 */
			uart {
				compatible = "renesas,rz-sci-uart"; /* in zephyr/dts/arm/renesas/rz/rzt/r9a07g074.dtsi:569 */
				current-speed = < 0x1c200 >;        /* in zephyr/dts/arm/renesas/rz/rzt/r9a07g074.dtsi:570 */
				status = "disabled";                /* in zephyr/dts/arm/renesas/rz/rzt/r9a07g074.dtsi:571 */
			};
		};

		/* node '/soc/sci5@81001000' defined in zephyr/dts/arm/renesas/rz/rzt/r9a07g074.dtsi:575 */
		sci5: sci5@81001000 {
			compatible = "renesas,rz-sci";       /* in zephyr/dts/arm/renesas/rz/rzt/r9a07g074.dtsi:576 */
			reg = < 0x81001000 0x400 >;          /* in zephyr/dts/arm/renesas/rz/rzt/r9a07g074.dtsi:577 */
			channel = < 0x5 >;                   /* in zephyr/dts/arm/renesas/rz/rzt/r9a07g074.dtsi:578 */
			interrupts = < 0x0 0x1b3 0x2 0xa0 >,
			             < 0x0 0x1b4 0x4 0xa0 >,
			             < 0x0 0x1b5 0x4 0xa0 >,
			             < 0x0 0x1b6 0x2 0xa0 >; /* in zephyr/dts/arm/renesas/rz/rzt/r9a07g074.dtsi:579 */
			interrupt-names = "eri",
			                  "rxi",
			                  "txi",
			                  "tei";             /* in zephyr/dts/arm/renesas/rz/rzt/r9a07g074.dtsi:583 */
			status = "disabled";                 /* in zephyr/dts/arm/renesas/rz/rzt/r9a07g074.dtsi:584 */

			/* node '/soc/sci5@81001000/uart' defined in zephyr/dts/arm/renesas/rz/rzt/r9a07g074.dtsi:586 */
			uart {
				compatible = "renesas,rz-sci-uart"; /* in zephyr/dts/arm/renesas/rz/rzt/r9a07g074.dtsi:587 */
				current-speed = < 0x1c200 >;        /* in zephyr/dts/arm/renesas/rz/rzt/r9a07g074.dtsi:588 */
				status = "disabled";                /* in zephyr/dts/arm/renesas/rz/rzt/r9a07g074.dtsi:589 */
			};
		};
	};

	/* node '/cpus' defined in zephyr/dts/arm/renesas/rz/rzt/r9a07g074.dtsi:16 */
	cpus {
		#address-cells = < 0x1 >; /* in zephyr/dts/arm/renesas/rz/rzt/r9a07g074.dtsi:17 */
		#size-cells = < 0x0 >;    /* in zephyr/dts/arm/renesas/rz/rzt/r9a07g074.dtsi:18 */

		/* node '/cpus/cpu@0' defined in zephyr/dts/arm/renesas/rz/rzt/r9a07g074.dtsi:20 */
		cpu@0 {
			device_type = "cpu";           /* in zephyr/dts/arm/renesas/rz/rzt/r9a07g074.dtsi:21 */
			compatible = "arm,cortex-r52"; /* in zephyr/dts/arm/renesas/rz/rzt/r9a07g074.dtsi:22 */
			reg = < 0x0 >;                 /* in zephyr/dts/arm/renesas/rz/rzt/r9a07g074.dtsi:23 */
		};
	};

	/* node '/timer' defined in zephyr/dts/arm/renesas/rz/rzt/r9a07g074.dtsi:27 */
	arch_timer: timer {
		compatible = "arm,armv8-timer";    /* in zephyr/dts/arm/renesas/rz/rzt/r9a07g074.dtsi:28 */
		interrupts = < 0x1 0xd 0x2 0xa0 >,
		             < 0x1 0xe 0x2 0xa0 >,
		             < 0x1 0xb 0x2 0xa0 >,
		             < 0x1 0xa 0x2 0xa0 >; /* in zephyr/dts/arm/renesas/rz/rzt/r9a07g074.dtsi:29 */
		interrupt-parent = < &gic >;       /* in zephyr/dts/arm/renesas/rz/rzt/r9a07g074.dtsi:33 */
	};

	/* node '/leds' defined in zephyr/boards/renesas/rzt2l_rsk/rzt2l_rsk.dts:30 */
	leds {
		compatible = "gpio-leds"; /* in zephyr/boards/renesas/rzt2l_rsk/rzt2l_rsk.dts:31 */

		/* node '/leds/led1' defined in zephyr/boards/renesas/rzt2l_rsk/rzt2l_rsk.dts:33 */
		led1: led1 {
			gpios = < &gpio17 0x6 0x0 >; /* in zephyr/boards/renesas/rzt2l_rsk/rzt2l_rsk.dts:34 */
			label = "led1";              /* in zephyr/boards/renesas/rzt2l_rsk/rzt2l_rsk.dts:35 */
		};

		/* node '/leds/led3' defined in zephyr/boards/renesas/rzt2l_rsk/rzt2l_rsk.dts:38 */
		led3: led3 {
			gpios = < &gpio18 0x1 0x0 >; /* in zephyr/boards/renesas/rzt2l_rsk/rzt2l_rsk.dts:39 */
			label = "led3";              /* in zephyr/boards/renesas/rzt2l_rsk/rzt2l_rsk.dts:40 */
		};
	};

	/* node '/gpio_keys' defined in zephyr/boards/renesas/rzt2l_rsk/rzt2l_rsk.dts:44 */
	gpio_keys {
		compatible = "gpio-keys"; /* in zephyr/boards/renesas/rzt2l_rsk/rzt2l_rsk.dts:45 */

		/* node '/gpio_keys/sw1' defined in zephyr/boards/renesas/rzt2l_rsk/rzt2l_rsk.dts:47 */
		sw1: sw1 {
			label = "sw1";               /* in zephyr/boards/renesas/rzt2l_rsk/rzt2l_rsk.dts:48 */
			gpios = < &gpio14 0x2 0x0 >; /* in zephyr/boards/renesas/rzt2l_rsk/rzt2l_rsk.dts:49 */
			zephyr,code = < 0xb >;       /* in zephyr/boards/renesas/rzt2l_rsk/rzt2l_rsk.dts:50 */
		};

		/* node '/gpio_keys/sw2' defined in zephyr/boards/renesas/rzt2l_rsk/rzt2l_rsk.dts:53 */
		sw2: sw2 {
			label = "sw2";               /* in zephyr/boards/renesas/rzt2l_rsk/rzt2l_rsk.dts:54 */
			gpios = < &gpio16 0x3 0x0 >; /* in zephyr/boards/renesas/rzt2l_rsk/rzt2l_rsk.dts:55 */
			zephyr,code = < 0x2 >;       /* in zephyr/boards/renesas/rzt2l_rsk/rzt2l_rsk.dts:56 */
		};
	};
};
